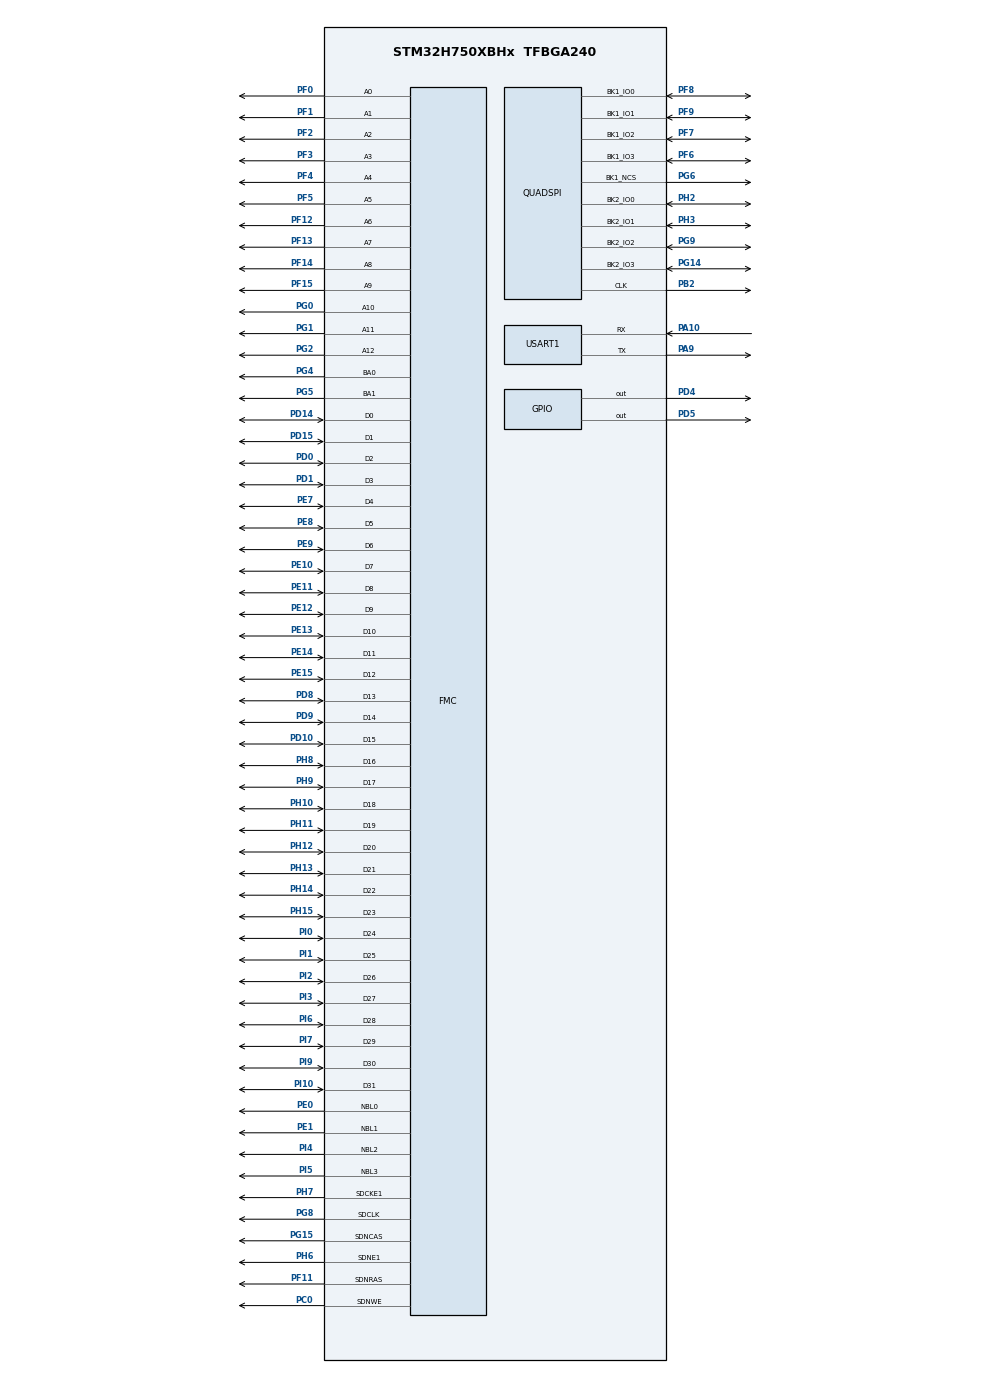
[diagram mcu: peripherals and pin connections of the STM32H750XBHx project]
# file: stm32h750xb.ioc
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CORTEX_M7.MPU_Control=__NULL
CORTEX_M7.default_mode_Activation=1
FMC.CASLatency1=FMC_SDRAM_CAS_LATENCY_3
FMC.ColumnBitsNumber1=FMC_SDRAM_COLUMN_BITS_NUM_9
FMC.ExitSelfRefreshDelay1=9
FMC.LoadToActiveDelay1=2
FMC.RCDDelay1=2
FMC.RPDelay1=2
FMC.ReadBurst1=FMC_SDRAM_RBURST_ENABLE
FMC.ReadPipeDelay1=FMC_SDRAM_RPIPE_DELAY_1
FMC.RowCycleDelay1=8
FMC.SDClockPeriod1=FMC_SDRAM_CLOCK_PERIOD_2
FMC.SelfRefreshTime1=6
FMC.WriteRecoveryTime1=4
Mcu.Family=STM32H7
Mcu.Name=STM32H750XBHx
Mcu.Package=TFBGA240
NVIC.PriorityGroup=NVIC_PRIORITYGROUP_4
PA10.Mode=Asynchronous
PA10.Signal=USART1_RX
PA9.Mode=Asynchronous
PA9.Signal=USART1_TX
PB2.GPIO_Speed=GPIO_SPEED_FREQ_VERY_HIGH
PB2.Mode=Dual_Bank
PB2.Signal=QUADSPI_CLK
PC0.GPIO_Speed_High_Default=GPIO_SPEED_FREQ_VERY_HIGH
PC0.Signal=FMC_SDNWE
PC14-OSC32_IN\ (OSC32_IN).Mode=LSE-External-Oscillator
PC14-OSC32_IN\ (OSC32_IN).Signal=RCC_OSC32_IN
PC15-OSC32_OUT\ (OSC32_OUT).Mode=LSE-External-Oscillator
PC15-OSC32_OUT\ (OSC32_OUT).Signal=RCC_OSC32_OUT
PD0.GPIO_Speed_High_Default=GPIO_SPEED_FREQ_VERY_HIGH
PD0.Signal=FMC_D2_DA2
PD1.GPIO_Speed_High_Default=GPIO_SPEED_FREQ_VERY_HIGH
PD1.Signal=FMC_D3_DA3
PD10.GPIO_Speed_High_Default=GPIO_SPEED_FREQ_VERY_HIGH
PD10.Signal=FMC_D15_DA15
PD14.GPIO_Speed_High_Default=GPIO_SPEED_FREQ_VERY_HIGH
PD14.Signal=FMC_D0_DA0
PD15.GPIO_Speed_High_Default=GPIO_SPEED_FREQ_VERY_HIGH
PD15.Signal=FMC_D1_DA1
PD4.PinState=GPIO_PIN_SET
PD4.Signal=GPIO_Output
PD5.PinState=GPIO_PIN_SET
PD5.Signal=GPIO_Output
PD8.GPIO_Speed_High_Default=GPIO_SPEED_FREQ_VERY_HIGH
PD8.Signal=FMC_D13_DA13
PD9.GPIO_Speed_High_Default=GPIO_SPEED_FREQ_VERY_HIGH
PD9.Signal=FMC_D14_DA14
PE0.GPIO_Speed_High_Default=GPIO_SPEED_FREQ_VERY_HIGH
PE0.Signal=FMC_NBL0
PE1.GPIO_Speed_High_Default=GPIO_SPEED_FREQ_VERY_HIGH
PE1.Signal=FMC_NBL1
PE10.GPIO_Speed_High_Default=GPIO_SPEED_FREQ_VERY_HIGH
PE10.Signal=FMC_D7_DA7
PE11.GPIO_Speed_High_Default=GPIO_SPEED_FREQ_VERY_HIGH
PE11.Signal=FMC_D8_DA8
PE12.GPIO_Speed_High_Default=GPIO_SPEED_FREQ_VERY_HIGH
PE12.Signal=FMC_D9_DA9
PE13.GPIO_Speed_High_Default=GPIO_SPEED_FREQ_VERY_HIGH
PE13.Signal=FMC_D10_DA10
PE14.GPIO_Speed_High_Default=GPIO_SPEED_FREQ_VERY_HIGH
PE14.Signal=FMC_D11_DA11
PE15.GPIO_Speed_High_Default=GPIO_SPEED_FREQ_VERY_HIGH
PE15.Signal=FMC_D12_DA12
PE7.GPIO_Speed_High_Default=GPIO_SPEED_FREQ_VERY_HIGH
PE7.Signal=FMC_D4_DA4
PE8.GPIO_Speed_High_Default=GPIO_SPEED_FREQ_VERY_HIGH
PE8.Signal=FMC_D5_DA5
PE9.GPIO_Speed_High_Default=GPIO_SPEED_FREQ_VERY_HIGH
PE9.Signal=FMC_D6_DA6
PF0.GPIO_Speed_High_Default=GPIO_SPEED_FREQ_VERY_HIGH
PF0.Signal=FMC_A0
PF1.GPIO_Speed_High_Default=GPIO_SPEED_FREQ_VERY_HIGH
PF1.Signal=FMC_A1
PF11.GPIO_Speed_High_Default=GPIO_SPEED_FREQ_VERY_HIGH
PF11.Signal=FMC_SDNRAS
PF12.GPIO_Speed_High_Default=GPIO_SPEED_FREQ_VERY_HIGH
PF12.Signal=FMC_A6
PF13.GPIO_Speed_High_Default=GPIO_SPEED_FREQ_VERY_HIGH
PF13.Signal=FMC_A7
PF14.GPIO_Speed_High_Default=GPIO_SPEED_FREQ_VERY_HIGH
PF14.Signal=FMC_A8
PF15.GPIO_Speed_High_Default=GPIO_SPEED_FREQ_VERY_HIGH
PF15.Signal=FMC_A9
PF2.GPIO_Speed_High_Default=GPIO_SPEED_FREQ_VERY_HIGH
PF2.Signal=FMC_A2
PF3.GPIO_Speed_High_Default=GPIO_SPEED_FREQ_VERY_HIGH
PF3.Signal=FMC_A3
PF4.GPIO_Speed_High_Default=GPIO_SPEED_FREQ_VERY_HIGH
PF4.Signal=FMC_A4
PF5.GPIO_Speed_High_Default=GPIO_SPEED_FREQ_VERY_HIGH
PF5.Signal=FMC_A5
PF6.GPIO_Speed=GPIO_SPEED_FREQ_VERY_HIGH
PF6.Mode=Dual_Bank
PF6.Signal=QUADSPI_BK1_IO3
PF7.GPIO_Speed=GPIO_SPEED_FREQ_VERY_HIGH
PF7.Mode=Dual_Bank
PF7.Signal=QUADSPI_BK1_IO2
PF8.GPIO_Speed=GPIO_SPEED_FREQ_VERY_HIGH
PF8.Mode=Dual_Bank
PF8.Signal=QUADSPI_BK1_IO0
PF9.GPIO_Speed=GPIO_SPEED_FREQ_VERY_HIGH
PF9.Mode=Dual_Bank
PF9.Signal=QUADSPI_BK1_IO1
PG0.GPIO_Speed_High_Default=GPIO_SPEED_FREQ_VERY_HIGH
PG0.Signal=FMC_A10
PG1.GPIO_Speed_High_Default=GPIO_SPEED_FREQ_VERY_HIGH
PG1.Signal=FMC_A11
PG14.GPIO_Speed=GPIO_SPEED_FREQ_VERY_HIGH
PG14.Mode=Dual_Bank
PG14.Signal=QUADSPI_BK2_IO3
PG15.GPIO_Speed_High_Default=GPIO_SPEED_FREQ_VERY_HIGH
PG15.Signal=FMC_SDNCAS
PG2.GPIO_Speed_High_Default=GPIO_SPEED_FREQ_VERY_HIGH
PG2.Signal=FMC_A12
PG4.GPIO_Speed_High_Default=GPIO_SPEED_FREQ_VERY_HIGH
PG4.Signal=FMC_A14_BA0
PG5.GPIO_Speed_High_Default=GPIO_SPEED_FREQ_VERY_HIGH
PG5.Signal=FMC_A15_BA1
PG6.GPIO_Speed=GPIO_SPEED_FREQ_VERY_HIGH
PG6.Mode=Enable Chip Select 1 for both banks
PG6.Signal=QUADSPI_BK1_NCS
PG8.GPIO_Speed_High_Default=GPIO_SPEED_FREQ_VERY_HIGH
PG8.Signal=FMC_SDCLK
PG9.GPIO_Speed=GPIO_SPEED_FREQ_VERY_HIGH
PG9.Mode=Dual_Bank
PG9.Signal=QUADSPI_BK2_IO2
PH0-OSC_IN\ (PH0).Mode=HSE-External-Oscillator
PH0-OSC_IN\ (PH0).Signal=RCC_OSC_IN
PH1-OSC_OUT\ (PH1).Mode=HSE-External-Oscillator
PH1-OSC_OUT\ (PH1).Signal=RCC_OSC_OUT
PH10.GPIO_Speed_High_Default=GPIO_SPEED_FREQ_VERY_HIGH
PH10.Signal=FMC_D18
PH11.GPIO_Speed_High_Default=GPIO_SPEED_FREQ_VERY_HIGH
PH11.Signal=FMC_D19
PH12.GPIO_Speed_High_Default=GPIO_SPEED_FREQ_VERY_HIGH
PH12.Signal=FMC_D20
PH13.GPIO_Speed_High_Default=GPIO_SPEED_FREQ_VERY_HIGH
PH13.Signal=FMC_D21
PH14.GPIO_Speed_High_Default=GPIO_SPEED_FREQ_VERY_HIGH
PH14.Signal=FMC_D22
PH15.GPIO_Speed_High_Default=GPIO_SPEED_FREQ_VERY_HIGH
PH15.Signal=FMC_D23
PH2.GPIO_Speed=GPIO_SPEED_FREQ_VERY_HIGH
PH2.Mode=Dual_Bank
PH2.Signal=QUADSPI_BK2_IO0
PH3.GPIO_Speed=GPIO_SPEED_FREQ_VERY_HIGH
PH3.Mode=Dual_Bank
PH3.Signal=QUADSPI_BK2_IO1
PH6.GPIO_Speed_High_Default=GPIO_SPEED_FREQ_VERY_HIGH
PH6.Mode=SdramChipSelect2_1
PH6.Signal=FMC_SDNE1
PH7.GPIO_Speed_High_Default=GPIO_SPEED_FREQ_VERY_HIGH
PH7.Mode=SdramChipSelect2_1
PH7.Signal=FMC_SDCKE1
PH8.GPIO_Speed_High_Default=GPIO_SPEED_FREQ_VERY_HIGH
PH8.Signal=FMC_D16
PH9.GPIO_Speed_High_Default=GPIO_SPEED_FREQ_VERY_HIGH
PH9.Signal=FMC_D17
PI0.GPIO_Speed_High_Default=GPIO_SPEED_FREQ_VERY_HIGH
PI0.Signal=FMC_D24
PI1.GPIO_Speed_High_Default=GPIO_SPEED_FREQ_VERY_HIGH
PI1.Signal=FMC_D25
PI10.GPIO_Speed_High_Default=GPIO_SPEED_FREQ_VERY_HIGH
PI10.Signal=FMC_D31
PI2.GPIO_Speed_High_Default=GPIO_SPEED_FREQ_VERY_HIGH
PI2.Signal=FMC_D26
PI3.GPIO_Speed_High_Default=GPIO_SPEED_FREQ_VERY_HIGH
PI3.Signal=FMC_D27
PI4.GPIO_Speed_High_Default=GPIO_SPEED_FREQ_VERY_HIGH
PI4.Signal=FMC_NBL2
PI5.GPIO_Speed_High_Default=GPIO_SPEED_FREQ_VERY_HIGH
PI5.Signal=FMC_NBL3
PI6.GPIO_Speed_High_Default=GPIO_SPEED_FREQ_VERY_HIGH
PI6.Signal=FMC_D28
PI7.GPIO_Speed_High_Default=GPIO_SPEED_FREQ_VERY_HIGH
PI7.Signal=FMC_D29
PI9.GPIO_Speed_High_Default=GPIO_SPEED_FREQ_VERY_HIGH
PI9.Signal=FMC_D30
ProjectManager.HeapSize=0x200
ProjectManager.StackSize=0x400
ProjectManager.TargetToolchain=MDK-ARM V5.32
QUADSPI.ChipSelectHighTime=QSPI_CS_HIGH_TIME_8_CYCLE
QUADSPI.ClockPrescaler=3
QUADSPI.FifoThreshold=32
QUADSPI.FlashSize=27
QUADSPI.SampleShifting=QSPI_SAMPLE_SHIFTING_NONE
RCC.ADCFreq_Value=480000000
RCC.APB1Freq_Value=120000000
RCC.APB2Freq_Value=120000000
RCC.APB3Freq_Value=120000000
RCC.APB4Freq_Value=120000000
RCC.CortexFreq_Value=480000000
RCC.D1PPRE=RCC_APB3_DIV2
RCC.D2PPRE1=RCC_APB1_DIV2
RCC.D2PPRE2=RCC_APB2_DIV2
RCC.D3PPRE=RCC_APB4_DIV2
RCC.DIVM1=5
RCC.DIVM2=5
RCC.DIVN1=192
RCC.DIVN2=192
RCC.HCLKFreq_Value=240000000
RCC.HPRE=RCC_HCLK_DIV2
RCC.PLLSourceVirtual=RCC_PLLSOURCE_HSE
RCC.ProductRev=revV
RCC.SYSCLKFreq_VALUE=480000000
RCC.SYSCLKSource=RCC_SYSCLKSOURCE_PLLCLK
RCC.USBFreq_Value=480000000
SH.FMC_A0.0=FMC_A0,13b-sda1
SH.FMC_A1.0=FMC_A1,13b-sda1
SH.FMC_A10.0=FMC_A10,13b-sda1
SH.FMC_A11.0=FMC_A11,13b-sda1
SH.FMC_A12.0=FMC_A12,13b-sda1
SH.FMC_A14_BA0.0=FMC_BA0,FourSdramBanks1
SH.FMC_A15_BA1.0=FMC_BA1,FourSdramBanks1
SH.FMC_A2.0=FMC_A2,13b-sda1
SH.FMC_A3.0=FMC_A3,13b-sda1
SH.FMC_A4.0=FMC_A4,13b-sda1
SH.FMC_A5.0=FMC_A5,13b-sda1
SH.FMC_A6.0=FMC_A6,13b-sda1
SH.FMC_A7.0=FMC_A7,13b-sda1
SH.FMC_A8.0=FMC_A8,13b-sda1
SH.FMC_A9.0=FMC_A9,13b-sda1
SH.FMC_D0_DA0.0=FMC_D0,sd-32b-d1
SH.FMC_D10_DA10.0=FMC_D10,sd-32b-d1
SH.FMC_D11_DA11.0=FMC_D11,sd-32b-d1
SH.FMC_D12_DA12.0=FMC_D12,sd-32b-d1
SH.FMC_D13_DA13.0=FMC_D13,sd-32b-d1
SH.FMC_D14_DA14.0=FMC_D14,sd-32b-d1
SH.FMC_D15_DA15.0=FMC_D15,sd-32b-d1
SH.FMC_D16.0=FMC_D16,sd-32b-d1
SH.FMC_D17.0=FMC_D17,sd-32b-d1
SH.FMC_D18.0=FMC_D18,sd-32b-d1
SH.FMC_D19.0=FMC_D19,sd-32b-d1
SH.FMC_D1_DA1.0=FMC_D1,sd-32b-d1
SH.FMC_D20.0=FMC_D20,sd-32b-d1
SH.FMC_D21.0=FMC_D21,sd-32b-d1
SH.FMC_D22.0=FMC_D22,sd-32b-d1
SH.FMC_D23.0=FMC_D23,sd-32b-d1
SH.FMC_D24.0=FMC_D24,sd-32b-d1
SH.FMC_D25.0=FMC_D25,sd-32b-d1
SH.FMC_D26.0=FMC_D26,sd-32b-d1
SH.FMC_D27.0=FMC_D27,sd-32b-d1
SH.FMC_D28.0=FMC_D28,sd-32b-d1
SH.FMC_D29.0=FMC_D29,sd-32b-d1
SH.FMC_D2_DA2.0=FMC_D2,sd-32b-d1
SH.FMC_D30.0=FMC_D30,sd-32b-d1
SH.FMC_D31.0=FMC_D31,sd-32b-d1
SH.FMC_D3_DA3.0=FMC_D3,sd-32b-d1
SH.FMC_D4_DA4.0=FMC_D4,sd-32b-d1
SH.FMC_D5_DA5.0=FMC_D5,sd-32b-d1
SH.FMC_D6_DA6.0=FMC_D6,sd-32b-d1
SH.FMC_D7_DA7.0=FMC_D7,sd-32b-d1
SH.FMC_D8_DA8.0=FMC_D8,sd-32b-d1
SH.FMC_D9_DA9.0=FMC_D9,sd-32b-d1
SH.FMC_NBL0.0=FMC_NBL0,Sd4ByteEnable1
SH.FMC_NBL1.0=FMC_NBL1,Sd4ByteEnable1
SH.FMC_NBL2.0=FMC_NBL2,Sd4ByteEnable1
SH.FMC_NBL3.0=FMC_NBL3,Sd4ByteEnable1
SH.FMC_SDCLK.0=FMC_SDCLK,13b-sda1
SH.FMC_SDNCAS.0=FMC_SDNCAS,13b-sda1
SH.FMC_SDNRAS.0=FMC_SDNRAS,13b-sda1
SH.FMC_SDNWE.0=FMC_SDNWE,13b-sda1
USART1.VirtualMode-Asynchronous=VM_ASYNC
board=custom

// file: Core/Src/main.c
/* USER CODE BEGIN Header */
/**
  ******************************************************************************
  * @file           : main.c
  * @brief          : Main program body
  ******************************************************************************
  * @attention
  *
  * Copyright (c) 2024 STMicroelectronics.
  * All rights reserved.
  *
  * This software is licensed under terms that can be found in the LICENSE file
  * in the root directory of this software component.
  * If no LICENSE file comes with this software, it is provided AS-IS.
  *
  ******************************************************************************
  */
/* USER CODE END Header */
#include "main.h"
#include "quadspi.h"
#include "usart.h"
#include "gpio.h"
#include "fmc.h"

/* USER CODE BEGIN Includes */
#include <stdarg.h>
#include <stdio.h>
#include "dual_w25q256jv.h"
/* USER CODE END Includes */

void SystemClock_Config(void);

/* USER CODE BEGIN 0 */
typedef void (*pFunction)(void);
static void JumpToApp(void)
{
    uint8_t i = 0;
    uint32_t app_ddr = QSPI_BASE;
    pFunction JumpApp = (pFunction)(*(__IO uint32_t *)(app_ddr + 4));

    /* close and reset Systick */
    SysTick->CTRL = 0;                  // disable systick
    SysTick->LOAD = 0;                  // clear loaded value
    SysTick->VAL = 0;                   // clear current systick value

    /* clear all NVIC Enable and Pending registers */
    for (uint8_t i = 0; i < 8; i++)
    {
        NVIC->ICER[i] = 0xFFFFFFFF;
        NVIC->ICPR[i] = 0xFFFFFFFF;
    }

    /* priviage mode */
    __set_CONTROL(0);

    /* disable global interrupt */
    __disable_irq();

    /* blocks all interrupts apart from the non-maskable interrupt (NMI) and the hard fault exception */
    __set_PRIMASK(1);

    __set_MSP(app_ddr);

    JumpApp();
}
/* USER CODE END 0 */

int main(void)
{

    /* MCU Configuration--------------------------------------------------------*/

    /* Reset of all peripherals, Initializes the Flash interface and the Systick. */
    HAL_Init();

    /* Configure the system clock */
    SystemClock_Config();

    /* Initialize all configured peripherals */
    MX_GPIO_Init();
    MX_QUADSPI_Init();
    MX_USART1_UART_Init();
    MX_FMC_Init();
    /* USER CODE BEGIN 2 */
    w25qxx_init();
    w25qxx_memorymapped();

    printf("  __  ____  ___   _   ____   ___   ___ _____ \r\n");
    printf(" |  \\/  \\ \\/ / | | | | __ ) / _ \\ / _ \\_   _| \r\n");
    printf(" | |\\/| |\\  /| |_| | |  _ \\| | | | | | || | \r\n");
    printf(" | |  | |/  \\|  _  | | |_) | |_| | |_| || | \r\n");
    printf(" |_|  |_/_/\\_\\_| |_| |____/ \\___/ \\___/ |_| \r\n");
    printf(" BootLoader Powered by MXH.\r\n");

    JumpToApp();
    /* USER CODE END 2 */

    /* Infinite loop */
    while (1)
    {

    }
}

void SystemClock_Config(void)
{
    RCC_OscInitTypeDef RCC_OscInitStruct = {0};
    RCC_ClkInitTypeDef RCC_ClkInitStruct = {0};

    /** Supply configuration update enable
    */
    HAL_PWREx_ConfigSupply(PWR_LDO_SUPPLY);

    /** Configure the main internal regulator output voltage
    */
    __HAL_PWR_VOLTAGESCALING_CONFIG(PWR_REGULATOR_VOLTAGE_SCALE1);

    while (!__HAL_PWR_GET_FLAG(PWR_FLAG_VOSRDY)) {}

    __HAL_RCC_SYSCFG_CLK_ENABLE();
    __HAL_PWR_VOLTAGESCALING_CONFIG(PWR_REGULATOR_VOLTAGE_SCALE0);

    while (!__HAL_PWR_GET_FLAG(PWR_FLAG_VOSRDY)) {}

    /** Initializes the RCC Oscillators according to the specified parameters
    * in the RCC_OscInitTypeDef structure.
    */
    RCC_OscInitStruct.OscillatorType = RCC_OSCILLATORTYPE_HSE;
    RCC_OscInitStruct.HSEState = RCC_HSE_ON;
    RCC_OscInitStruct.PLL.PLLState = RCC_PLL_ON;
    RCC_OscInitStruct.PLL.PLLSource = RCC_PLLSOURCE_HSE;
    RCC_OscInitStruct.PLL.PLLM = 5;
    RCC_OscInitStruct.PLL.PLLN = 192;
    RCC_OscInitStruct.PLL.PLLP = 2;
    RCC_OscInitStruct.PLL.PLLQ = 2;
    RCC_OscInitStruct.PLL.PLLR = 2;
    RCC_OscInitStruct.PLL.PLLRGE = RCC_PLL1VCIRANGE_2;
    RCC_OscInitStruct.PLL.PLLVCOSEL = RCC_PLL1VCOWIDE;
    RCC_OscInitStruct.PLL.PLLFRACN = 0;
    if (HAL_RCC_OscConfig(&RCC_OscInitStruct) != HAL_OK)
    {
        Error_Handler();
    }

    /** Initializes the CPU, AHB and APB buses clocks
    */
    RCC_ClkInitStruct.ClockType = RCC_CLOCKTYPE_HCLK | RCC_CLOCKTYPE_SYSCLK
                                  | RCC_CLOCKTYPE_PCLK1 | RCC_CLOCKTYPE_PCLK2
                                  | RCC_CLOCKTYPE_D3PCLK1 | RCC_CLOCKTYPE_D1PCLK1;
    RCC_ClkInitStruct.SYSCLKSource = RCC_SYSCLKSOURCE_PLLCLK;
    RCC_ClkInitStruct.SYSCLKDivider = RCC_SYSCLK_DIV1;
    RCC_ClkInitStruct.AHBCLKDivider = RCC_HCLK_DIV2;
    RCC_ClkInitStruct.APB3CLKDivider = RCC_APB3_DIV2;
    RCC_ClkInitStruct.APB1CLKDivider = RCC_APB1_DIV2;
    RCC_ClkInitStruct.APB2CLKDivider = RCC_APB2_DIV2;
    RCC_ClkInitStruct.APB4CLKDivider = RCC_APB4_DIV2;

    if (HAL_RCC_ClockConfig(&RCC_ClkInitStruct, FLASH_LATENCY_4) != HAL_OK)
    {
        Error_Handler();
    }
}

/* USER CODE BEGIN 4 */
/* ------------------redirect printf to uart-------------------*/
#if !defined(__MICROLIB)
#if defined(__GNUC__) || defined(__clang__)
    __asm(".global __use_no_semihosting\n\t");
#elif defined(__CC_ARM)
    #pragma import(__use_no_semihosting)
#endif

void _sys_exit(int x)
{
    x = x;
}

void _ttywrch(int ch) //__use_no_semihosting was requested, _ttywrch was
{
    ch = ch;
}

struct __FILE
{
    int handle;
};  // add this code in GNU environment
FILE __stdout;
#endif

#if defined(__GNUC__) && !defined(__clang__)
    #define PUTCHAR_PROTOTYPE int __io_putchar(int ch)
#else
    #define PUTCHAR_PROTOTYPE int fputc(int ch, FILE *f)
#endif
PUTCHAR_PROTOTYPE
{
    HAL_UART_Transmit(&huart1, (uint8_t *)&ch, 1, 1000);
    return ch;
}
/* USER CODE END 4 */

void Error_Handler(void)
{
    __disable_irq();
    while (1)
    {
    }
}
